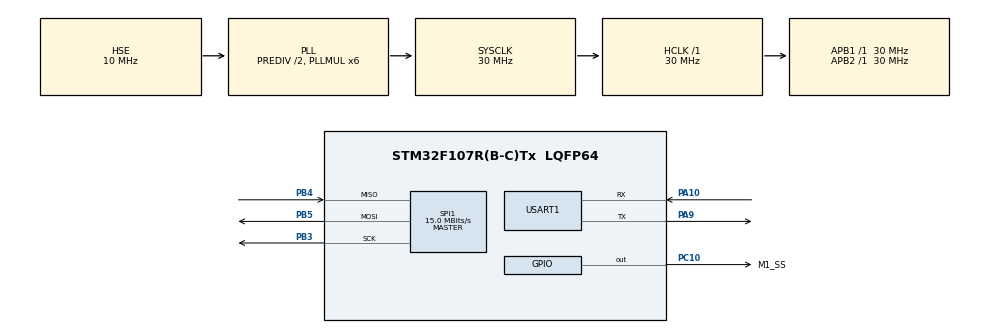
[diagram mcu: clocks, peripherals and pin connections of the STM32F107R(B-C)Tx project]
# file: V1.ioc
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FREERTOS.Tasks01=defaultTask,0,128,StartDefaultTask,Default,NULL,Dynamic,NULL,NULL
Mcu.Family=STM32F1
Mcu.Name=STM32F107R(B-C)Tx
Mcu.Package=LQFP64
NVIC.PriorityGroup=NVIC_PRIORITYGROUP_4
NVIC.SPI1_IRQn=true\:5\:0\:false\:false\:true\:true\:true\:true
NVIC.TIM1_UP_IRQn=true\:0\:0\:false\:false\:true\:false\:false\:true
NVIC.TimeBase=TIM1_UP_IRQn
NVIC.TimeBaseIP=TIM1
NVIC.USART1_IRQn=true\:5\:0\:false\:false\:true\:true\:true\:true
PA10.Mode=Asynchronous
PA10.Signal=USART1_RX
PA13.Mode=Serial_Wire
PA13.Signal=SYS_JTMS-SWDIO
PA14.Mode=Serial_Wire
PA14.Signal=SYS_JTCK-SWCLK
PA9.Mode=Asynchronous
PA9.Signal=USART1_TX
PB3.Mode=Full_Duplex_Master
PB3.Signal=SPI1_SCK
PB4.Mode=Full_Duplex_Master
PB4.Signal=SPI1_MISO
PB5.Mode=Full_Duplex_Master
PB5.Signal=SPI1_MOSI
PC10.GPIO_Label=M1_SS
PC10.GPIO_Speed=GPIO_SPEED_FREQ_MEDIUM
PC10.Signal=GPIO_Output
PD0-OSC_IN.Mode=HSE-External-Oscillator
PD0-OSC_IN.Signal=RCC_OSC_IN
PD1-OSC_OUT.Mode=HSE-External-Oscillator
PD1-OSC_OUT.Signal=RCC_OSC_OUT
ProjectManager.HeapSize=0x200
ProjectManager.StackSize=0x400
ProjectManager.TargetToolchain=STM32CubeIDE
RCC.AHBFreq_Value=30000000
RCC.APB1Freq_Value=30000000
RCC.APB1TimFreq_Value=30000000
RCC.APB2Freq_Value=30000000
RCC.APB2TimFreq_Value=30000000
RCC.HCLKFreq_Value=30000000
RCC.HSEDivPLL=RCC_HSE_PREDIV_DIV2
RCC.HSE_VALUE=10000000
RCC.PLLMUL=RCC_PLL_MUL6
RCC.PLLSourceVirtual=RCC_PLLSOURCE_HSE
RCC.SYSCLKFreq_VALUE=30000000
RCC.SYSCLKSource=RCC_SYSCLKSOURCE_PLLCLK
RCC.USBFreq_Value=20000000
SPI1.BaudRatePrescaler=SPI_BAUDRATEPRESCALER_2
SPI1.CalculateBaudRate=15.0 MBits/s
SPI1.Direction=SPI_DIRECTION_2LINES
SPI1.Mode=SPI_MODE_MASTER
SPI1.VirtualType=VM_MASTER
USART1.VirtualMode=VM_ASYNC
VP_FREERTOS_VS_CMSIS_V1.Mode=CMSIS_V1
VP_SYS_VS_tim1.Mode=TIM1
board=custom

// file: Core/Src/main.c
/* USER CODE BEGIN Header */
/**
  ******************************************************************************
  * @file           : main.c
  * @brief          : Main program body
  ******************************************************************************
  * @attention
  *
  * <h2><center>&copy; Copyright (c) 2021 STMicroelectronics.
  * All rights reserved.</center></h2>
  *
  * This software component is licensed by ST under BSD 3-Clause license,
  * the "License"; You may not use this file except in compliance with the
  * License. You may obtain a copy of the License at:
  *                        opensource.org/licenses/BSD-3-Clause
  *
  ******************************************************************************
  */
/* USER CODE END Header */
#include "main.h"
#include "cmsis_os.h"

SPI_HandleTypeDef hspi1;

UART_HandleTypeDef huart1;

osThreadId defaultTaskHandle;

void SystemClock_Config(void);
static void MX_GPIO_Init(void);
static void MX_SPI1_Init(void);
static void MX_USART1_UART_Init(void);
void StartDefaultTask(void const * argument);

int main(void)
{

  /* MCU Configuration--------------------------------------------------------*/

  /* Reset of all peripherals, Initializes the Flash interface and the Systick. */
  HAL_Init();

  /* Configure the system clock */
  SystemClock_Config();

  /* Initialize all configured peripherals */
  MX_GPIO_Init();
  MX_SPI1_Init();
  MX_USART1_UART_Init();

  /* Create the thread(s) */
  /* definition and creation of defaultTask */
  osThreadDef(defaultTask, StartDefaultTask, osPriorityNormal, 0, 128);
  defaultTaskHandle = osThreadCreate(osThread(defaultTask), NULL);

  /* Start scheduler */
  osKernelStart();

  /* We should never get here as control is now taken by the scheduler */
  /* Infinite loop */
  while (1)
  {

  }
}

void SystemClock_Config(void)
{
  RCC_OscInitTypeDef RCC_OscInitStruct = {0};
  RCC_ClkInitTypeDef RCC_ClkInitStruct = {0};

  /** Initializes the RCC Oscillators according to the specified parameters
  * in the RCC_OscInitTypeDef structure.
  */
  RCC_OscInitStruct.OscillatorType = RCC_OSCILLATORTYPE_HSE;
  RCC_OscInitStruct.HSEState = RCC_HSE_ON;
  RCC_OscInitStruct.HSEPredivValue = RCC_HSE_PREDIV_DIV2;
  RCC_OscInitStruct.HSIState = RCC_HSI_ON;
  RCC_OscInitStruct.Prediv1Source = RCC_PREDIV1_SOURCE_HSE;
  RCC_OscInitStruct.PLL.PLLState = RCC_PLL_ON;
  RCC_OscInitStruct.PLL.PLLSource = RCC_PLLSOURCE_HSE;
  RCC_OscInitStruct.PLL.PLLMUL = RCC_PLL_MUL6;
  RCC_OscInitStruct.PLL2.PLL2State = RCC_PLL_NONE;
  if (HAL_RCC_OscConfig(&RCC_OscInitStruct) != HAL_OK)
  {
    Error_Handler();
  }
  /** Initializes the CPU, AHB and APB buses clocks
  */
  RCC_ClkInitStruct.ClockType = RCC_CLOCKTYPE_HCLK|RCC_CLOCKTYPE_SYSCLK
                              |RCC_CLOCKTYPE_PCLK1|RCC_CLOCKTYPE_PCLK2;
  RCC_ClkInitStruct.SYSCLKSource = RCC_SYSCLKSOURCE_PLLCLK;
  RCC_ClkInitStruct.AHBCLKDivider = RCC_SYSCLK_DIV1;
  RCC_ClkInitStruct.APB1CLKDivider = RCC_HCLK_DIV1;
  RCC_ClkInitStruct.APB2CLKDivider = RCC_HCLK_DIV1;

  if (HAL_RCC_ClockConfig(&RCC_ClkInitStruct, FLASH_LATENCY_1) != HAL_OK)
  {
    Error_Handler();
  }
  /** Configure the Systick interrupt time
  */
  __HAL_RCC_PLLI2S_ENABLE();
}

static void MX_SPI1_Init(void)
{

  /* SPI1 parameter configuration*/
  hspi1.Instance = SPI1;
  hspi1.Init.Mode = SPI_MODE_MASTER;
  hspi1.Init.Direction = SPI_DIRECTION_2LINES;
  hspi1.Init.DataSize = SPI_DATASIZE_8BIT;
  hspi1.Init.CLKPolarity = SPI_POLARITY_LOW;
  hspi1.Init.CLKPhase = SPI_PHASE_1EDGE;
  hspi1.Init.NSS = SPI_NSS_SOFT;
  hspi1.Init.BaudRatePrescaler = SPI_BAUDRATEPRESCALER_2;
  hspi1.Init.FirstBit = SPI_FIRSTBIT_MSB;
  hspi1.Init.TIMode = SPI_TIMODE_DISABLE;
  hspi1.Init.CRCCalculation = SPI_CRCCALCULATION_DISABLE;
  hspi1.Init.CRCPolynomial = 10;
  if (HAL_SPI_Init(&hspi1) != HAL_OK)
  {
    Error_Handler();
  }

}

static void MX_USART1_UART_Init(void)
{

  huart1.Instance = USART1;
  huart1.Init.BaudRate = 115200;
  huart1.Init.WordLength = UART_WORDLENGTH_8B;
  huart1.Init.StopBits = UART_STOPBITS_1;
  huart1.Init.Parity = UART_PARITY_NONE;
  huart1.Init.Mode = UART_MODE_TX_RX;
  huart1.Init.HwFlowCtl = UART_HWCONTROL_NONE;
  huart1.Init.OverSampling = UART_OVERSAMPLING_16;
  if (HAL_UART_Init(&huart1) != HAL_OK)
  {
    Error_Handler();
  }

}

static void MX_GPIO_Init(void)
{
  GPIO_InitTypeDef GPIO_InitStruct = {0};

  /* GPIO Ports Clock Enable */
  __HAL_RCC_GPIOD_CLK_ENABLE();
  __HAL_RCC_GPIOA_CLK_ENABLE();
  __HAL_RCC_GPIOC_CLK_ENABLE();
  __HAL_RCC_GPIOB_CLK_ENABLE();

  /*Configure GPIO pin Output Level */
  HAL_GPIO_WritePin(M1_SS_GPIO_Port, M1_SS_Pin, GPIO_PIN_RESET);

  /*Configure GPIO pin : M1_SS_Pin */
  GPIO_InitStruct.Pin = M1_SS_Pin;
  GPIO_InitStruct.Mode = GPIO_MODE_OUTPUT_PP;
  GPIO_InitStruct.Pull = GPIO_NOPULL;
  GPIO_InitStruct.Speed = GPIO_SPEED_FREQ_MEDIUM;
  HAL_GPIO_Init(M1_SS_GPIO_Port, &GPIO_InitStruct);

}

void StartDefaultTask(void const * argument)
{
  /* USER CODE BEGIN 5 */
  /* Infinite loop */
	uint8_t tx_byte=0x9F;
	uint32_t rx_byte;
	HAL_GPIO_WritePin(M1_SS_GPIO_Port, M1_SS_Pin, GPIO_PIN_SET);

  for(;;)
  {
	HAL_GPIO_WritePin(M1_SS_GPIO_Port, M1_SS_Pin, GPIO_PIN_RESET);
	HAL_SPI_Transmit(&hspi1,&tx_byte, 1,200);

	//HAL_SPI_Transmit(&hspi1,"\0x00", 1,200);
	HAL_SPI_Receive(&hspi1,&rx_byte, 4,200);
	HAL_UART_Transmit(&huart1,&rx_byte,4,100);

	HAL_GPIO_WritePin(M1_SS_GPIO_Port, M1_SS_Pin, GPIO_PIN_SET);

    osDelay(2000);
  }
  /* USER CODE END 5 */
}

 /**
  * @brief  Period elapsed callback in non blocking mode
  * @note   This function is called  when TIM1 interrupt took place, inside
  * HAL_TIM_IRQHandler(). It makes a direct call to HAL_IncTick() to increment
  * a global variable "uwTick" used as application time base.
  * @param  htim : TIM handle
  * @retval None
  */
void HAL_TIM_PeriodElapsedCallback(TIM_HandleTypeDef *htim)
{
  if (htim->Instance == TIM1) {
    HAL_IncTick();
  }
}

void Error_Handler(void)
{
  __disable_irq();
  while (1)
  {
  }
}

/************************ (C) COPYRIGHT STMicroelectronics *****END OF FILE****/
